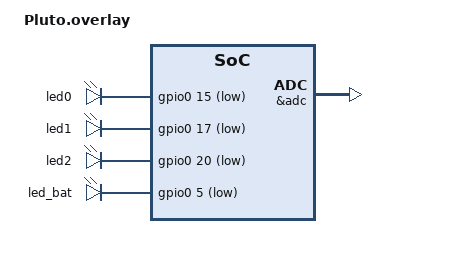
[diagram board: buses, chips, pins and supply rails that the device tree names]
&adc {
	status = "okay";
	io-channels = <&adc 0>;   // battery read on P0.11
};

&pwm0 {
	pinctrl-0 = <&pwm0_default>;
	pinctrl-1 = <&pwm0_sleep>;
};

&pwm0_default {
	group1 {
		psels = <NRF_PSEL(PWM_OUT0, 0, 15)>, <NRF_PSEL(PWM_OUT1, 0, 17)>, <NRF_PSEL(PWM_OUT2, 0, 20)>;
		nordic,drive-mode = <NRF_DRIVE_D0S1>;
		nordic,invert;
	};
};

pwmleds {
	pwm_led0: pwm_led_0 { pwms = <&pwm0 0 PWM_MSEC(1) PWM_POLARITY_INVERTED>; };
	pwm_led1: pwm_led_1 { pwms = <&pwm0 1 PWM_MSEC(1) PWM_POLARITY_INVERTED>; };
	pwm_led2: pwm_led_2 { pwms = <&pwm0 2 PWM_MSEC(1) PWM_POLARITY_INVERTED>; };
};

leds {
	led0: led_0 { gpios = <&gpio0 15 (GPIO_OPEN_DRAIN | GPIO_ACTIVE_LOW)>; };
	led1: led_1 { gpios = <&gpio0 17 (GPIO_OPEN_DRAIN | GPIO_ACTIVE_LOW)>; };
	led2: led_2 { gpios = <&gpio0 20 (GPIO_OPEN_DRAIN | GPIO_ACTIVE_LOW)>; };
	led_bat: led_3 { gpios = <&gpio0 5 (GPIO_OPEN_DRAIN | GPIO_ACTIVE_LOW)>; };
};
